AUTOSAR XML (schema 4-3-1)
package /TPC_Composition/Components
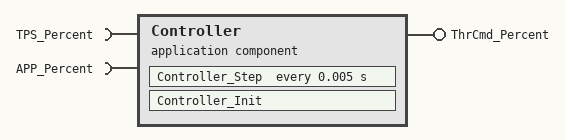
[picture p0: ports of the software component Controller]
  application sw component type Controller
    require port TPS_Percent: nonqueued-receiver-com-spec{data-element=Value, init-value=0}, required-interface=TPS_Percent
    require port APP_Percent: nonqueued-receiver-com-spec{data-element=Value, init-value=0}, required-interface=APP_Percent
    provide port ThrCmd_Percent: nonqueued-sender-com-spec{data-element=Value, init-value=0}, provided-interface=ThrCmd_Percent
    behavior Controller_IB: handle-termination-and-restart=NO-SUPPORT
      timing event Event_Controller_Step: start-on-event=Controller_Step, period=0.005
      runnable Controller_Init
      runnable Controller_Step
        data-read-access:
          access IN_TPS_Percent_Value: accessed-variable=TPS_Percent.Value
          access IN_APP_Percent_Value: accessed-variable=APP_Percent.Value
        data-write-access:
          access OUT_ThrCmd_Percent_Value: accessed-variable=ThrCmd_Percent.Value
